# CY8C5267AXI_LP051 register map
File version: 0.1
CY8C52LP
Registers are 8-bit, read-write, no defined reset value unless marked. A register's access mark holds for its fields unless they carry their own. Offsets are from the block's base; lines under a group give offsets from that group; [hi:lo] are bit positions; {n}, {i} and the like mark numbered series; 'fields as' and 'values as' point back to an identical list; <NAME> marks a mode.

## Memory map
0x00000000 PWM_1
0x40006478 Control_Reg_1
0x4000657B Control_Reg_2

## PWM_1
Base 0x00000000
0x40006528 PWM_1__COMPARE1 — UDB.D0 - Assigned Compare1 Value
0x40006538 PWM_1__COMPARE2 — UDB.D1 - Assigned Compare2 Value
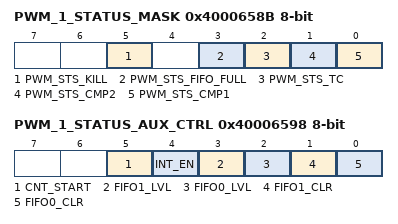
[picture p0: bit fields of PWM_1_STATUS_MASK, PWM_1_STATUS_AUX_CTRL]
0x4000658B PWM_1_STATUS_MASK — UDB Status bits Interrupt Mask Enable Register
  [5] PWM_STS_KILL ro — Enables the Interrupt on Kill
  [3] PWM_STS_FIFO_FULL ro — FIFO Full Status Mask
  [2] PWM_STS_TC ro — Enables the Interrupt on Terminal Count
  [1] PWM_STS_CMP2 ro — Enables the Interrupt on Compare 2
  [0] PWM_STS_CMP1 ro — Enables the Interrupt on Compare 1
0x40006598 PWM_1_STATUS_AUX_CTRL — UDB Auxilliary Control Register
  [5] CNT_START — FIFO0 clear
    0=E_CNT_START0 (Disable counter); 1=E_CNT_START1 (Enable counter)
  [4] INT_EN
    0=E_INT_EN0 (Interrupt disabled); 1=E_INT_EN1 (Interrupt enabled)
  [3] FIFO1_LVL — FIFO level
    0=E_FIFO_LVL_0 (FIFO LVL: input mode: FIFO not full; output mode: FIFO not empty); 1=E_FIFO_LVL_1 (FIFO LVL: input mode: FIFO at least 1/2 empty; output mode: FIFO at least 1/2 full)
  [2] FIFO0_LVL — FIFO level
    values as FIFO1_LVL
  [1] FIFO1_CLR — FIFO1 clear
    0=E_FIFO_CLR_0 (Normal FIFO operation); 1=E_FIFO_CLR_1 (Clear FIFO state)
  [0] FIFO0_CLR — FIFO0 clear
    values as FIFO1_CLR

## Control_Reg_1
Base 0x40006478
0x00 Control_Reg_1_CONTROL_REG

## Control_Reg_2
Base 0x4000657B
Registers as Control_Reg_1 (with Control_Reg_1 read as Control_Reg_2).
